AUTOSAR XML (schema 00050)
package /body_control/lighting/swc
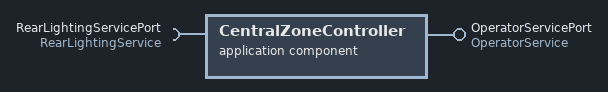
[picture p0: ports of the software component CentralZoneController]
  application sw component type CentralZoneController
    provide port OperatorServicePort: provided-interface=OperatorService
    require port RearLightingServicePort: required-interface=RearLightingService
  application sw component type RearLightingNode
    provide port RearLightingServicePort: provided-interface=RearLightingService
  application sw component type HmiClient
    require port OperatorServicePort: required-interface=OperatorService
  composition sw component type BCL_Composition
    component CentralZoneController: type=CentralZoneController
    component RearLightingNode: type=RearLightingNode
    component HmiClient: type=HmiClient
    connect CentralZoneController.OperatorServicePort -> HmiClient.OperatorServicePort
    connect RearLightingNode.RearLightingServicePort -> CentralZoneController.RearLightingServicePort
